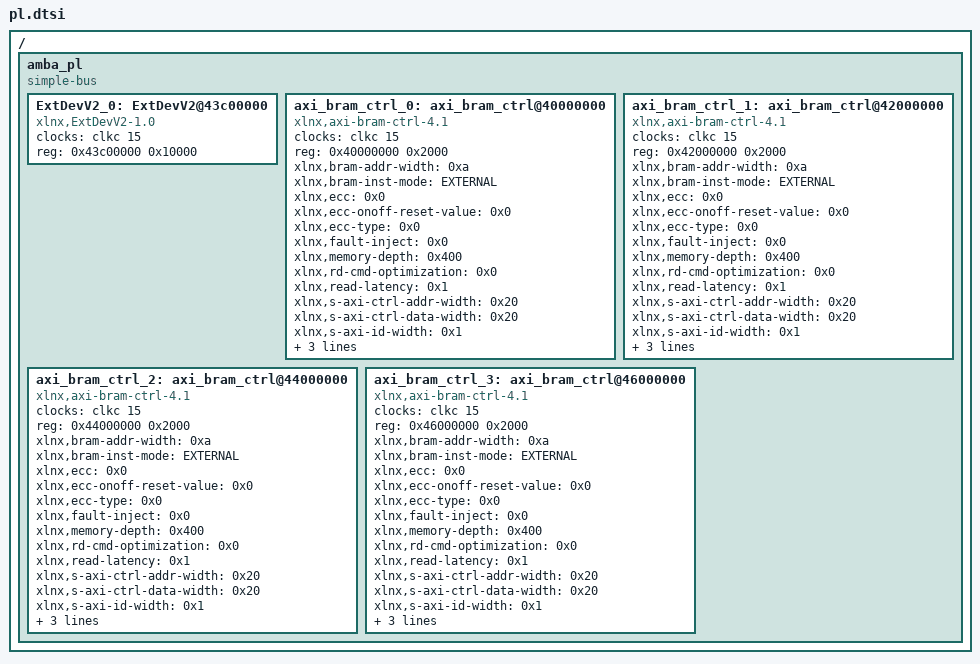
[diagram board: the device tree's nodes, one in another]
/*
 * CAUTION: This file is automatically generated by Xilinx.
 * Version: XSCT 2018.3
 * Today is: Tue Dec 23 09:01:07 2025
 */


/ {
	amba_pl: amba_pl {
		#address-cells = <1>;
		#size-cells = <1>;
		compatible = "simple-bus";
		ranges ;
		ExtDevV2_0: ExtDevV2@43c00000 {
			/* This is a place holder node for a custom IP, user may need to update the entries */
			clock-names = "ApbClk";
			clocks = <&clkc 15>;
			compatible = "xlnx,ExtDevV2-1.0";
			reg = <0x43c00000 0x10000>;
		};
		axi_bram_ctrl_0: axi_bram_ctrl@40000000 {
			/* This is a place holder node for a custom IP, user may need to update the entries */
			clock-names = "s_axi_aclk";
			clocks = <&clkc 15>;
			compatible = "xlnx,axi-bram-ctrl-4.1";
			reg = <0x40000000 0x2000>;
			xlnx,bram-addr-width = <0xa>;
			xlnx,bram-inst-mode = "EXTERNAL";
			xlnx,ecc = <0x0>;
			xlnx,ecc-onoff-reset-value = <0x0>;
			xlnx,ecc-type = <0x0>;
			xlnx,fault-inject = <0x0>;
			xlnx,memory-depth = <0x400>;
			xlnx,rd-cmd-optimization = <0x0>;
			xlnx,read-latency = <0x1>;
			xlnx,s-axi-ctrl-addr-width = <0x20>;
			xlnx,s-axi-ctrl-data-width = <0x20>;
			xlnx,s-axi-id-width = <0x1>;
			xlnx,s-axi-supports-narrow-burst = <0x0>;
			xlnx,select-xpm = <0x1>;
			xlnx,single-port-bram = <0x1>;
		};
		axi_bram_ctrl_1: axi_bram_ctrl@42000000 {
			/* This is a place holder node for a custom IP, user may need to update the entries */
			clock-names = "s_axi_aclk";
			clocks = <&clkc 15>;
			compatible = "xlnx,axi-bram-ctrl-4.1";
			reg = <0x42000000 0x2000>;
			xlnx,bram-addr-width = <0xa>;
			xlnx,bram-inst-mode = "EXTERNAL";
			xlnx,ecc = <0x0>;
			xlnx,ecc-onoff-reset-value = <0x0>;
			xlnx,ecc-type = <0x0>;
			xlnx,fault-inject = <0x0>;
			xlnx,memory-depth = <0x400>;
			xlnx,rd-cmd-optimization = <0x0>;
			xlnx,read-latency = <0x1>;
			xlnx,s-axi-ctrl-addr-width = <0x20>;
			xlnx,s-axi-ctrl-data-width = <0x20>;
			xlnx,s-axi-id-width = <0x1>;
			xlnx,s-axi-supports-narrow-burst = <0x0>;
			xlnx,select-xpm = <0x1>;
			xlnx,single-port-bram = <0x1>;
		};
		axi_bram_ctrl_2: axi_bram_ctrl@44000000 {
			/* This is a place holder node for a custom IP, user may need to update the entries */
			clock-names = "s_axi_aclk";
			clocks = <&clkc 15>;
			compatible = "xlnx,axi-bram-ctrl-4.1";
			reg = <0x44000000 0x2000>;
			xlnx,bram-addr-width = <0xa>;
			xlnx,bram-inst-mode = "EXTERNAL";
			xlnx,ecc = <0x0>;
			xlnx,ecc-onoff-reset-value = <0x0>;
			xlnx,ecc-type = <0x0>;
			xlnx,fault-inject = <0x0>;
			xlnx,memory-depth = <0x400>;
			xlnx,rd-cmd-optimization = <0x0>;
			xlnx,read-latency = <0x1>;
			xlnx,s-axi-ctrl-addr-width = <0x20>;
			xlnx,s-axi-ctrl-data-width = <0x20>;
			xlnx,s-axi-id-width = <0x1>;
			xlnx,s-axi-supports-narrow-burst = <0x0>;
			xlnx,select-xpm = <0x1>;
			xlnx,single-port-bram = <0x1>;
		};
		axi_bram_ctrl_3: axi_bram_ctrl@46000000 {
			/* This is a place holder node for a custom IP, user may need to update the entries */
			clock-names = "s_axi_aclk";
			clocks = <&clkc 15>;
			compatible = "xlnx,axi-bram-ctrl-4.1";
			reg = <0x46000000 0x2000>;
			xlnx,bram-addr-width = <0xa>;
			xlnx,bram-inst-mode = "EXTERNAL";
			xlnx,ecc = <0x0>;
			xlnx,ecc-onoff-reset-value = <0x0>;
			xlnx,ecc-type = <0x0>;
			xlnx,fault-inject = <0x0>;
			xlnx,memory-depth = <0x400>;
			xlnx,rd-cmd-optimization = <0x0>;
			xlnx,read-latency = <0x1>;
			xlnx,s-axi-ctrl-addr-width = <0x20>;
			xlnx,s-axi-ctrl-data-width = <0x20>;
			xlnx,s-axi-id-width = <0x1>;
			xlnx,s-axi-supports-narrow-burst = <0x0>;
			xlnx,select-xpm = <0x1>;
			xlnx,single-port-bram = <0x1>;
		};
	};
};
